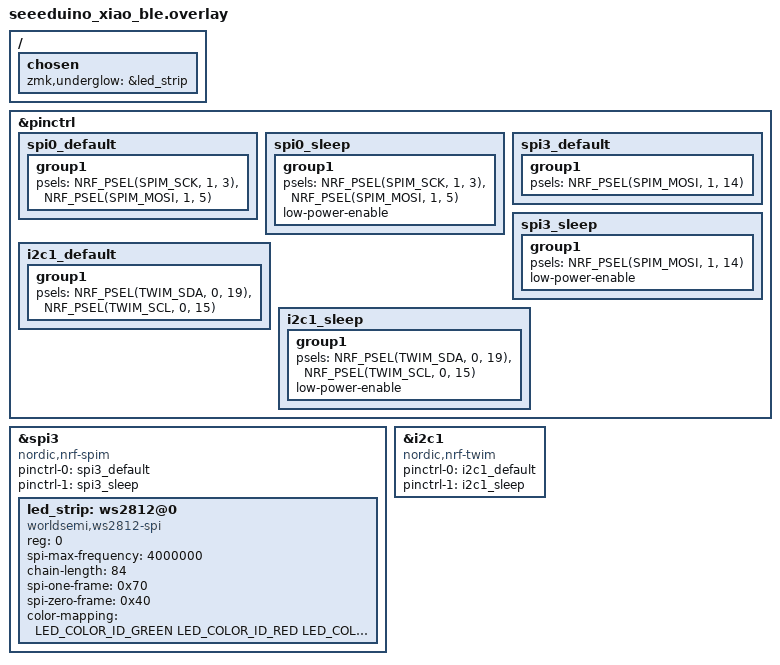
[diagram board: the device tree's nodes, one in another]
#include <dt-bindings/led/led.h>

&pinctrl {
    spi0_default: spi0_default {
        group1 {
            psels = <NRF_PSEL(SPIM_SCK, 1, 3)>,
                    <NRF_PSEL(SPIM_MOSI, 1, 5)>;
        };
    };

    spi0_sleep: spi0_sleep {
        group1 {
            psels = <NRF_PSEL(SPIM_SCK, 1, 3)>,
                    <NRF_PSEL(SPIM_MOSI, 1, 5)>;
            low-power-enable;
        };
    };

    spi3_default: spi3_default {
        group1 {
            psels = <NRF_PSEL(SPIM_MOSI, 1, 14)>;
        };
    };

    spi3_sleep: spi3_sleep {
        group1 {
            psels = <NRF_PSEL(SPIM_MOSI, 1, 14)>;
            low-power-enable;
        };
    };

    i2c1_default: i2c1_default {
        group1 {
            psels = <NRF_PSEL(TWIM_SDA, 0, 19)>,
                    <NRF_PSEL(TWIM_SCL, 0, 15)>;
        };
    };

    i2c1_sleep: i2c1_sleep {
        group1 {
            psels = <NRF_PSEL(TWIM_SDA, 0, 19)>,
                    <NRF_PSEL(TWIM_SCL, 0, 15)>;
            low-power-enable;
        };
    };
};


&spi3 {
    compatible = "nordic,nrf-spim";
    status = "okay";
    pinctrl-0 = <&spi3_default>;
    pinctrl-1 = <&spi3_sleep>;
    pinctrl-names = "default", "sleep";

    led_strip: ws2812@0 {
        compatible = "worldsemi,ws2812-spi";
        reg = <0>;
        spi-max-frequency = <4000000>;
        chain-length = <84>;
        spi-one-frame = <0x70>;
        spi-zero-frame = <0x40>;
        color-mapping = <LED_COLOR_ID_GREEN LED_COLOR_ID_RED LED_COLOR_ID_BLUE>;
    };
};

&i2c1 {
    status = "okay";
    compatible = "nordic,nrf-twim";
    pinctrl-0 = <&i2c1_default>;
    pinctrl-1 = <&i2c1_sleep>;
    pinctrl-names = "default", "sleep";
};

/ {
    chosen {
        zmk,underglow = &led_strip;
    };
};
